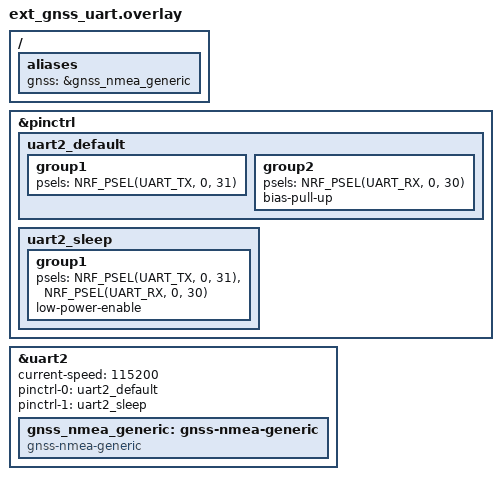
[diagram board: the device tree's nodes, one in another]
/*
 * Copyright (c) 2025 Nordic Semiconductor ASA
 *
 * SPDX-License-Identifier: LicenseRef-Nordic-5-Clause
 */

/ {
	aliases {
		gnss = &gnss_nmea_generic;
	};
};

&pinctrl {
	uart2_default: uart2_default {
		group1 {
			psels = <NRF_PSEL(UART_TX, 0, 31)>;
		};

		group2 {
			psels = <NRF_PSEL(UART_RX, 0, 30)>;
			bias-pull-up;
		};
	};

	uart2_sleep: uart2_sleep {
		group1 {
			psels = <NRF_PSEL(UART_TX, 0, 31)>,
				<NRF_PSEL(UART_RX, 0, 30)>;
			low-power-enable;
		};
	};
};

&uart2 {
	status = "okay";
	current-speed = <115200>;
	pinctrl-0 = <&uart2_default>;
	pinctrl-1 = <&uart2_sleep>;
	pinctrl-names = "default", "sleep";

	gnss_nmea_generic: gnss-nmea-generic {
		status = "okay";
		compatible = "gnss-nmea-generic";
	};
};
